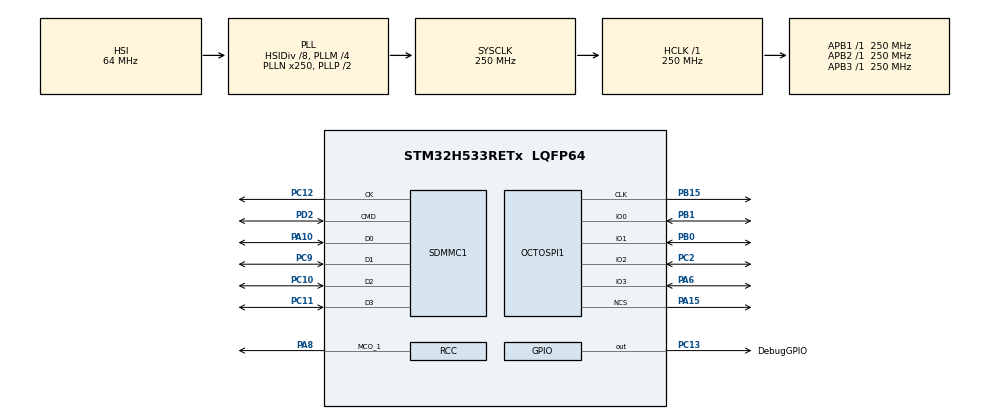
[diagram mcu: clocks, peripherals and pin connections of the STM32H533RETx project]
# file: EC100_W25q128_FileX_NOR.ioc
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BOOTPATH.BootPathName=LEGACY
BOOTPATH.UserSelectedBootPath=LEGACY
CORTEX_M33_NS.userName=CORTEX_M33
FILEX.FILEX_APPLICATION_THREAD_STACK_SIZE=14000
FILEX.FORMAT_NOR_OSPI_MEDIA=0
FILEX.FX_APP_MEM_POOL_SIZE=20000
FILEX.FX_FAT_MAP_SIZE=1024
FILEX.FX_LX_NOR_INTERFACE=1
FILEX.FX_MEDIA_DISABLE_SEARCH_CACHE=1
FILEX.FX_SD_INTERFACE=1
FILEX.LINK_NOR_OSPI_DRIVER=1
FILEX.LINK_SD_DRIVER=1
FILEX.useRTOS=1
GPDMA1.DESTINC_GPDMACH1=DMA_DINC_INCREMENTED
GPDMA1.DIRECTION_GPDMACH0=DMA_MEMORY_TO_PERIPH
GPDMA1.DMAHANDLE_GPDMACH0=hdmatx
GPDMA1.IPHANDLE_GPDMACH0-SIMPLEREQUEST_GPDMACH0=__NULL
GPDMA1.IPHANDLE_GPDMACH1-SIMPLEREQUEST_GPDMACH1=__NULL
GPDMA1.REQUEST_GPDMACH0=GPDMA1_REQUEST_OCTOSPI1
GPDMA1.REQUEST_GPDMACH1=GPDMA1_REQUEST_OCTOSPI1
GPDMA1.SRCINC_GPDMACH0=DMA_SINC_INCREMENTED
LEVELX.LX_DIRECT_READ=0
LEVELX.LX_DRIVER_CALLS_OSPI_INIT=0
LEVELX.LX_DRIVER_ERASES_OSPI_AFTER_INIT=0
LEVELX.LX_FREE_SECTOR_DATA_VERIFY=0
LEVELX.LX_NOR_ENABLE_MAPPING_BITMAP=1
LEVELX.LX_NOR_ENABLE_OBSOLETE_COUNT_CACHE=1
LEVELX.LX_NOR_Flash_Support=1
LEVELX.LX_NOR_SECTOR_SIZE=512
LEVELX.LX_OctoSPI_Memory_Interface=1
LevelX.BSP.number=1
LevelX0.BSP.STBoard=false
LevelX0.BSP.api=BSP_COMPONENT_DRIVER
LevelX0.BSP.component=custom
LevelX0.BSP.instance=custom
LevelX0.BSP.name=OSPI Component
LevelX0.BSP.semaphore=SEMA_CUSTOM
LevelX0.BSP.solution=custom
Mcu.Family=STM32H5
Mcu.Name=STM32H533RETx
Mcu.Package=LQFP64
NVIC.GPDMA1_Channel0_IRQn=true\:0\:0\:false\:false\:true\:false\:true\:true\:true
NVIC.GPDMA1_Channel1_IRQn=true\:0\:0\:false\:false\:true\:false\:true\:true\:true
NVIC.OCTOSPI1_IRQn=true\:0\:0\:false\:false\:true\:false\:true\:true\:true
NVIC.PriorityGroup=NVIC_PRIORITYGROUP_4
NVIC.SDMMC1_IRQn=true\:0\:0\:false\:false\:true\:false\:true\:true\:true
NVIC.TIM6_IRQn=true\:15\:0\:false\:false\:true\:false\:false\:true\:true
NVIC.TimeBase=TIM6_IRQn
NVIC.TimeBaseIP=TIM6
OCTOSPI1.ChipSelectHighTimeCycle=1
OCTOSPI1.ClockMode=HAL_XSPI_CLOCK_MODE_3
OCTOSPI1.ClockPrescaler=2
OCTOSPI1.MemorySize=HAL_XSPI_SIZE_128MB
OCTOSPI1.MemoryType=HAL_XSPI_MEMTYPE_MACRONIX
PA0.Signal=SPI3_RDY
PA10.Mode=SD_4_bits_Wide_bus
PA10.Signal=SDMMC1_D0
PA11.Signal=FDCAN1_RX
PA12.Signal=FDCAN1_TX
PA13(JTMS/SWDIO).Mode=Serial_Wire
PA13(JTMS/SWDIO).Signal=DEBUG_JTMS-SWDIO
PA14(JTCK/SWCLK).Mode=Serial_Wire
PA14(JTCK/SWCLK).Signal=DEBUG_JTCK-SWCLK
PA15(JTDI).Mode=quad_mode
PA15(JTDI).Signal=OCTOSPI1_NCS
PA2.Signal=USART2_TX
PA3.Signal=USART2_RX
PA4.Signal=COMP_DAC11_group
PA5.Signal=COMP_DAC12_group
PA6.Mode=OCTOSPI1_IO[3\:0]
PA6.Signal=OCTOSPI1_IO3
PA7.Signal=ADCx_INP7
PA8.Mode=Clock-out
PA8.Signal=RCC_MCO_1
PA9.Signal=SPI2_SCK
PB0.Mode=OCTOSPI1_IO[3\:0]
PB0.Signal=OCTOSPI1_IO1
PB1.Mode=OCTOSPI1_IO[3\:0]
PB1.Signal=OCTOSPI1_IO0
PB10.Signal=USART3_TX
PB12.Signal=SPI2_NSS
PB13.Signal=UART5_TX
PB14.Signal=SPI2_MISO
PB15.Mode=quad_mode
PB15.Signal=OCTOSPI1_CLK
PB2.Signal=SPI3_MOSI
PB3(JTDO/TRACESWO).Signal=SPI3_SCK
PB4(NJTRST).Signal=SPI3_MISO
PB5.Signal=UART5_RX
PB6.Signal=I2C1_SCL
PB7.Signal=I2C1_SDA
PB8.Signal=SPI3_NSS
PC0.Signal=ADCx_INP10
PC1.Signal=ADCx_INP11
PC10.Mode=SD_4_bits_Wide_bus
PC10.Signal=SDMMC1_D2
PC11.Mode=SD_4_bits_Wide_bus
PC11.Signal=SDMMC1_D3
PC12.Mode=SD_4_bits_Wide_bus
PC12.Signal=SDMMC1_CK
PC13.GPIO_Label=DebugGPIO
PC13.Signal=GPIO_Output
PC14-OSC32_IN(OSC32_IN).Signal=RCC_OSC32_IN
PC15-OSC32_OUT(OSC32_OUT).Signal=RCC_OSC32_OUT
PC2.Mode=OCTOSPI1_IO[3\:0]
PC2.Signal=OCTOSPI1_IO2
PC3.Signal=SPI2_MOSI
PC4.Signal=USART3_RX
PC5.Signal=ADCx_INP8
PC6.Signal=USART6_TX
PC7.Signal=USART6_RX
PC8.Signal=UART5_DE
PC9.Mode=SD_4_bits_Wide_bus
PC9.Signal=SDMMC1_D1
PD2.Mode=SD_4_bits_Wide_bus
PD2.Signal=SDMMC1_CMD
PH0-OSC_IN(PH0).Signal=RCC_OSC_IN
PH1-OSC_OUT(PH1).Signal=RCC_OSC_OUT
ProjectManager.HeapSize=0x200
ProjectManager.StackSize=0x400
ProjectManager.TargetToolchain=STM32CubeIDE
RCC.ADCFreq_Value=250000000
RCC.AHBFreq_Value=250000000
RCC.APB1Freq_Value=250000000
RCC.APB1TimFreq_Value=250000000
RCC.APB2Freq_Value=250000000
RCC.APB2TimFreq_Value=250000000
RCC.APB3Freq_Value=250000000
RCC.CSI_VALUE=4000000
RCC.CortexFreq_Value=250000000
RCC.EPOD_VALUE=8000000
RCC.HCLKFreq_Value=250000000
RCC.HSE_VALUE=25000000
RCC.HSI48_VALUE=48000000
RCC.HSIDiv=RCC_HSI_DIV8
RCC.HSI_VALUE=64000000
RCC.LSE_VALUE=32768
RCC.LSIRC_VALUE=32000
RCC.OCTOSPIMCLockSelection=RCC_OSPICLKSOURCE_CLKP
RCC.PLL2M=4
RCC.PLL2N=100
RCC.PLL2R=4
RCC.PLL2Source=RCC_PLL2_SOURCE_HSI
RCC.PLL3N=50
RCC.PLLM=4
RCC.PLLN=250
RCC.PLLSourceVirtual=RCC_PLL1_SOURCE_HSI
RCC.SPI2CLockSelection=RCC_SPI2CLKSOURCE_CLKP
RCC.SPI3CLockSelection=RCC_SPI3CLKSOURCE_PLL3P
RCC.SYSCLKFreq_VALUE=250000000
RCC.SYSCLKSource=RCC_SYSCLKSOURCE_PLLCLK
RCC.USBFreq_Value=48000000
RCC.VCOOutputFreq_Value=500000000
SDMMC1.ClockDiv=0
SH.ADCx_INP10.0=ADC1_INP10
SH.ADCx_INP11.0=ADC1_INP11
SH.ADCx_INP7.0=ADC1_INP7
SH.ADCx_INP8.0=ADC1_INP8
SH.COMP_DAC11_group.0=DAC1_OUT1
SH.COMP_DAC12_group.0=DAC1_OUT2
STMicroelectronics.X-CUBE-FREERTOS.1.3.1.configUSE_NEWLIB_REENTRANT=1
VP_BOOTPATH_VS_BOOTPATH.Mode=BP_Activate
VP_CORTEX_M33_NS_VS_Hclk.Mode=Hclk_Mode
VP_DCACHE1_VS_DCACHE.Mode=DCACHE_Activate
VP_FILEX_VS_FileOoSystemJjFileXJjCore.Mode=FileX_Core
VP_FILEX_VS_LevelXOoNOROointerface.Mode=LevelX_NOR_interface
VP_FILEX_VS_SDOointerface.Mode=SD_interface
VP_GPDMA1_VS_GPDMACH0.Mode=SIMPLEREQUEST_GPDMACH0
VP_GPDMA1_VS_GPDMACH1.Mode=SIMPLEREQUEST_GPDMACH1
VP_ICACHE_VS_ICACHE.Mode=DefaultMode
VP_LEVELX_VS_FileOoSystemJjLevelXJjNOR.Mode=LevelX_NOR_Flash_Support
VP_LEVELX_VS_OctoSPIOomemoryOointerface.Mode=OctoSPI_memory_interface
VP_MEMORYMAP_VS_MEMORYMAP.Mode=CurAppReg
VP_PWR_VS_LPOM.Mode=PowerOptimisation
VP_PWR_VS_SECSignals.Mode=Security/Privilege
VP_SYS_VS_tim6.Mode=TIM6
VP_THREADX_VS_RTOSJjThreadXJjCoreJjDefault.Mode=Core_Default
board=custom

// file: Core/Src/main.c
/* USER CODE BEGIN Header */
/**
  ******************************************************************************
  * @file           : main.c
  * @brief          : Main program body
  ******************************************************************************
  * @attention
  *
  * Copyright (c) 2025 STMicroelectronics.
  * All rights reserved.
  *
  * This software is licensed under terms that can be found in the LICENSE file
  * in the root directory of this software component.
  * If no LICENSE file comes with this software, it is provided AS-IS.
  *
  ******************************************************************************
  */
/* USER CODE END Header */
#include "app_threadx.h"
#include "main.h"

DCACHE_HandleTypeDef hdcache1;

XSPI_HandleTypeDef hospi1;
DMA_HandleTypeDef handle_GPDMA1_Channel1;
DMA_HandleTypeDef handle_GPDMA1_Channel0;

SD_HandleTypeDef hsd1;

void SystemClock_Config(void);
void PeriphCommonClock_Config(void);
static void MX_GPIO_Init(void);
static void MX_GPDMA1_Init(void);
static void MX_OCTOSPI1_Init(void);
static void MX_ICACHE_Init(void);
static void MX_DCACHE1_Init(void);
static void MX_SDMMC1_SD_Init(void);
/* USER CODE BEGIN PFP */

void W25Q128EnableWrite(void);
void W25Q128BorradoCompleto();
extern void Formateo();
/* USER CODE END PFP */

int main(void)
{

  /* MCU Configuration--------------------------------------------------------*/

  /* Reset of all peripherals, Initializes the Flash interface and the Systick. */
  HAL_Init();

  /* Configure the system clock */
  SystemClock_Config();

  /* Configure the peripherals common clocks */
  PeriphCommonClock_Config();

  /* Initialize all configured peripherals */
  MX_GPIO_Init();
  MX_GPDMA1_Init();
  MX_OCTOSPI1_Init();
  MX_ICACHE_Init();
  MX_DCACHE1_Init();
  MX_SDMMC1_SD_Init();

  MX_ThreadX_Init();

  /* We should never get here as control is now taken by the scheduler */

  /* Infinite loop */
  while (1)
  {

  }
}

void SystemClock_Config(void)
{
  RCC_OscInitTypeDef RCC_OscInitStruct = {0};
  RCC_ClkInitTypeDef RCC_ClkInitStruct = {0};

  /** Configure the main internal regulator output voltage
  */
  __HAL_PWR_VOLTAGESCALING_CONFIG(PWR_REGULATOR_VOLTAGE_SCALE0);

  while(!__HAL_PWR_GET_FLAG(PWR_FLAG_VOSRDY)) {}

  /** Initializes the RCC Oscillators according to the specified parameters
  * in the RCC_OscInitTypeDef structure.
  */
  RCC_OscInitStruct.OscillatorType = RCC_OSCILLATORTYPE_HSI;
  RCC_OscInitStruct.HSIState = RCC_HSI_ON;
  RCC_OscInitStruct.HSIDiv = RCC_HSI_DIV8;
  RCC_OscInitStruct.HSICalibrationValue = RCC_HSICALIBRATION_DEFAULT;
  RCC_OscInitStruct.PLL.PLLState = RCC_PLL_ON;
  RCC_OscInitStruct.PLL.PLLSource = RCC_PLL1_SOURCE_HSI;
  RCC_OscInitStruct.PLL.PLLM = 4;
  RCC_OscInitStruct.PLL.PLLN = 250;
  RCC_OscInitStruct.PLL.PLLP = 2;
  RCC_OscInitStruct.PLL.PLLQ = 2;
  RCC_OscInitStruct.PLL.PLLR = 2;
  RCC_OscInitStruct.PLL.PLLRGE = RCC_PLL1_VCIRANGE_1;
  RCC_OscInitStruct.PLL.PLLVCOSEL = RCC_PLL1_VCORANGE_WIDE;
  RCC_OscInitStruct.PLL.PLLFRACN = 0;
  if (HAL_RCC_OscConfig(&RCC_OscInitStruct) != HAL_OK)
  {
    Error_Handler();
  }

  /** Initializes the CPU, AHB and APB buses clocks
  */
  RCC_ClkInitStruct.ClockType = RCC_CLOCKTYPE_HCLK|RCC_CLOCKTYPE_SYSCLK
                              |RCC_CLOCKTYPE_PCLK1|RCC_CLOCKTYPE_PCLK2
                              |RCC_CLOCKTYPE_PCLK3;
  RCC_ClkInitStruct.SYSCLKSource = RCC_SYSCLKSOURCE_PLLCLK;
  RCC_ClkInitStruct.AHBCLKDivider = RCC_SYSCLK_DIV1;
  RCC_ClkInitStruct.APB1CLKDivider = RCC_HCLK_DIV1;
  RCC_ClkInitStruct.APB2CLKDivider = RCC_HCLK_DIV1;
  RCC_ClkInitStruct.APB3CLKDivider = RCC_HCLK_DIV1;

  if (HAL_RCC_ClockConfig(&RCC_ClkInitStruct, FLASH_LATENCY_5) != HAL_OK)
  {
    Error_Handler();
  }
  HAL_RCC_MCOConfig(RCC_MCO1, RCC_MCO1SOURCE_HSI, RCC_MCODIV_1);

  /** Configure the programming delay
  */
  __HAL_FLASH_SET_PROGRAM_DELAY(FLASH_PROGRAMMING_DELAY_2);
}

void PeriphCommonClock_Config(void)
{
  RCC_PeriphCLKInitTypeDef PeriphClkInitStruct = {0};

  /** Initializes the peripherals clock
  */
  PeriphClkInitStruct.PeriphClockSelection = RCC_PERIPHCLK_CKPER;
  PeriphClkInitStruct.CkperClockSelection = RCC_CLKPSOURCE_HSI;
  if (HAL_RCCEx_PeriphCLKConfig(&PeriphClkInitStruct) != HAL_OK)
  {
    Error_Handler();
  }
}

static void MX_DCACHE1_Init(void)
{

  hdcache1.Instance = DCACHE1;
  hdcache1.Init.ReadBurstType = DCACHE_READ_BURST_WRAP;
  if (HAL_DCACHE_Init(&hdcache1) != HAL_OK)
  {
    Error_Handler();
  }

}

static void MX_GPDMA1_Init(void)
{

  /* Peripheral clock enable */
  __HAL_RCC_GPDMA1_CLK_ENABLE();

  /* GPDMA1 interrupt Init */
    HAL_NVIC_SetPriority(GPDMA1_Channel0_IRQn, 0, 0);
    HAL_NVIC_EnableIRQ(GPDMA1_Channel0_IRQn);
    HAL_NVIC_SetPriority(GPDMA1_Channel1_IRQn, 0, 0);
    HAL_NVIC_EnableIRQ(GPDMA1_Channel1_IRQn);

}

static void MX_ICACHE_Init(void)
{

  /** Enable instruction cache (default 2-ways set associative cache)
  */
  if (HAL_ICACHE_Enable() != HAL_OK)
  {
    Error_Handler();
  }

}

static void MX_OCTOSPI1_Init(void)
{

  /* OCTOSPI1 parameter configuration*/
  hospi1.Instance = OCTOSPI1;
  hospi1.Init.FifoThresholdByte = 1;
  hospi1.Init.MemoryMode = HAL_XSPI_SINGLE_MEM;
  hospi1.Init.MemoryType = HAL_XSPI_MEMTYPE_MACRONIX;
  hospi1.Init.MemorySize = HAL_XSPI_SIZE_128MB;
  hospi1.Init.ChipSelectHighTimeCycle = 1;
  hospi1.Init.FreeRunningClock = HAL_XSPI_FREERUNCLK_DISABLE;
  hospi1.Init.ClockMode = HAL_XSPI_CLOCK_MODE_3;
  hospi1.Init.WrapSize = HAL_XSPI_WRAP_NOT_SUPPORTED;
  hospi1.Init.ClockPrescaler = 2;
  hospi1.Init.SampleShifting = HAL_XSPI_SAMPLE_SHIFT_NONE;
  hospi1.Init.DelayHoldQuarterCycle = HAL_XSPI_DHQC_DISABLE;
  hospi1.Init.ChipSelectBoundary = HAL_XSPI_BONDARYOF_NONE;
  hospi1.Init.DelayBlockBypass = HAL_XSPI_DELAY_BLOCK_BYPASS;
  hospi1.Init.Refresh = 0;
  if (HAL_XSPI_Init(&hospi1) != HAL_OK)
  {
    Error_Handler();
  }

}

static void MX_SDMMC1_SD_Init(void)
{

  hsd1.Instance = SDMMC1;
  hsd1.Init.ClockEdge = SDMMC_CLOCK_EDGE_RISING;
  hsd1.Init.ClockPowerSave = SDMMC_CLOCK_POWER_SAVE_DISABLE;
  hsd1.Init.BusWide = SDMMC_BUS_WIDE_4B;
  hsd1.Init.HardwareFlowControl = SDMMC_HARDWARE_FLOW_CONTROL_DISABLE;
  hsd1.Init.ClockDiv = 0;
  if (HAL_SD_Init(&hsd1) != HAL_OK)
  {
    Error_Handler();
  }

}

static void MX_GPIO_Init(void)
{
  GPIO_InitTypeDef GPIO_InitStruct = {0};

  /* GPIO Ports Clock Enable */
  __HAL_RCC_GPIOC_CLK_ENABLE();
  __HAL_RCC_GPIOH_CLK_ENABLE();
  __HAL_RCC_GPIOA_CLK_ENABLE();
  __HAL_RCC_GPIOB_CLK_ENABLE();
  __HAL_RCC_GPIOD_CLK_ENABLE();

  /*Configure GPIO pin Output Level */
  HAL_GPIO_WritePin(DebugGPIO_GPIO_Port, DebugGPIO_Pin, GPIO_PIN_RESET);

  /*Configure GPIO pin : DebugGPIO_Pin */
  GPIO_InitStruct.Pin = DebugGPIO_Pin;
  GPIO_InitStruct.Mode = GPIO_MODE_OUTPUT_PP;
  GPIO_InitStruct.Pull = GPIO_NOPULL;
  GPIO_InitStruct.Speed = GPIO_SPEED_FREQ_LOW;
  HAL_GPIO_Init(DebugGPIO_GPIO_Port, &GPIO_InitStruct);

  /*Configure GPIO pins : PC0 PC1 PC5 */
  GPIO_InitStruct.Pin = GPIO_PIN_0|GPIO_PIN_1|GPIO_PIN_5;
  GPIO_InitStruct.Mode = GPIO_MODE_ANALOG;
  GPIO_InitStruct.Pull = GPIO_NOPULL;
  HAL_GPIO_Init(GPIOC, &GPIO_InitStruct);

  /*Configure GPIO pin : PC3 */
  GPIO_InitStruct.Pin = GPIO_PIN_3;
  GPIO_InitStruct.Mode = GPIO_MODE_AF_PP;
  GPIO_InitStruct.Pull = GPIO_NOPULL;
  GPIO_InitStruct.Speed = GPIO_SPEED_FREQ_LOW;
  GPIO_InitStruct.Alternate = GPIO_AF5_SPI2;
  HAL_GPIO_Init(GPIOC, &GPIO_InitStruct);

  /*Configure GPIO pin : PA0 */
  GPIO_InitStruct.Pin = GPIO_PIN_0;
  GPIO_InitStruct.Mode = GPIO_MODE_AF_PP;
  GPIO_InitStruct.Pull = GPIO_NOPULL;
  GPIO_InitStruct.Speed = GPIO_SPEED_FREQ_LOW;
  GPIO_InitStruct.Alternate = GPIO_AF6_SPI3;
  HAL_GPIO_Init(GPIOA, &GPIO_InitStruct);

  /*Configure GPIO pins : PA2 PA3 */
  GPIO_InitStruct.Pin = GPIO_PIN_2|GPIO_PIN_3;
  GPIO_InitStruct.Mode = GPIO_MODE_AF_PP;
  GPIO_InitStruct.Pull = GPIO_NOPULL;
  GPIO_InitStruct.Speed = GPIO_SPEED_FREQ_LOW;
  GPIO_InitStruct.Alternate = GPIO_AF7_USART2;
  HAL_GPIO_Init(GPIOA, &GPIO_InitStruct);

  /*Configure GPIO pins : PA4 PA5 PA7 */
  GPIO_InitStruct.Pin = GPIO_PIN_4|GPIO_PIN_5|GPIO_PIN_7;
  GPIO_InitStruct.Mode = GPIO_MODE_ANALOG;
  GPIO_InitStruct.Pull = GPIO_NOPULL;
  HAL_GPIO_Init(GPIOA, &GPIO_InitStruct);

  /*Configure GPIO pin : PC4 */
  GPIO_InitStruct.Pin = GPIO_PIN_4;
  GPIO_InitStruct.Mode = GPIO_MODE_AF_PP;
  GPIO_InitStruct.Pull = GPIO_NOPULL;
  GPIO_InitStruct.Speed = GPIO_SPEED_FREQ_LOW;
  GPIO_InitStruct.Alternate = GPIO_AF7_USART3;
  HAL_GPIO_Init(GPIOC, &GPIO_InitStruct);

  /*Configure GPIO pin : PB2 */
  GPIO_InitStruct.Pin = GPIO_PIN_2;
  GPIO_InitStruct.Mode = GPIO_MODE_AF_PP;
  GPIO_InitStruct.Pull = GPIO_NOPULL;
  GPIO_InitStruct.Speed = GPIO_SPEED_FREQ_LOW;
  GPIO_InitStruct.Alternate = GPIO_AF7_SPI3;
  HAL_GPIO_Init(GPIOB, &GPIO_InitStruct);

  /*Configure GPIO pin : PB10 */
  GPIO_InitStruct.Pin = GPIO_PIN_10;
  GPIO_InitStruct.Mode = GPIO_MODE_AF_PP;
  GPIO_InitStruct.Pull = GPIO_NOPULL;
  GPIO_InitStruct.Speed = GPIO_SPEED_FREQ_LOW;
  GPIO_InitStruct.Alternate = GPIO_AF7_USART3;
  HAL_GPIO_Init(GPIOB, &GPIO_InitStruct);

  /*Configure GPIO pins : PB12 PB14 */
  GPIO_InitStruct.Pin = GPIO_PIN_12|GPIO_PIN_14;
  GPIO_InitStruct.Mode = GPIO_MODE_AF_PP;
  GPIO_InitStruct.Pull = GPIO_NOPULL;
  GPIO_InitStruct.Speed = GPIO_SPEED_FREQ_LOW;
  GPIO_InitStruct.Alternate = GPIO_AF5_SPI2;
  HAL_GPIO_Init(GPIOB, &GPIO_InitStruct);

  /*Configure GPIO pins : PB13 PB5 */
  GPIO_InitStruct.Pin = GPIO_PIN_13|GPIO_PIN_5;
  GPIO_InitStruct.Mode = GPIO_MODE_AF_PP;
  GPIO_InitStruct.Pull = GPIO_NOPULL;
  GPIO_InitStruct.Speed = GPIO_SPEED_FREQ_LOW;
  GPIO_InitStruct.Alternate = GPIO_AF14_UART5;
  HAL_GPIO_Init(GPIOB, &GPIO_InitStruct);

  /*Configure GPIO pins : PC6 PC7 */
  GPIO_InitStruct.Pin = GPIO_PIN_6|GPIO_PIN_7;
  GPIO_InitStruct.Mode = GPIO_MODE_AF_PP;
  GPIO_InitStruct.Pull = GPIO_NOPULL;
  GPIO_InitStruct.Speed = GPIO_SPEED_FREQ_LOW;
  GPIO_InitStruct.Alternate = GPIO_AF7_USART6;
  HAL_GPIO_Init(GPIOC, &GPIO_InitStruct);

  /*Configure GPIO pin : PC8 */
  GPIO_InitStruct.Pin = GPIO_PIN_8;
  GPIO_InitStruct.Mode = GPIO_MODE_AF_PP;
  GPIO_InitStruct.Pull = GPIO_NOPULL;
  GPIO_InitStruct.Speed = GPIO_SPEED_FREQ_LOW;
  GPIO_InitStruct.Alternate = GPIO_AF8_UART5;
  HAL_GPIO_Init(GPIOC, &GPIO_InitStruct);

  /*Configure GPIO pin : PA8 */
  GPIO_InitStruct.Pin = GPIO_PIN_8;
  GPIO_InitStruct.Mode = GPIO_MODE_AF_PP;
  GPIO_InitStruct.Pull = GPIO_NOPULL;
  GPIO_InitStruct.Speed = GPIO_SPEED_FREQ_LOW;
  GPIO_InitStruct.Alternate = GPIO_AF0_MCO;
  HAL_GPIO_Init(GPIOA, &GPIO_InitStruct);

  /*Configure GPIO pin : PA9 */
  GPIO_InitStruct.Pin = GPIO_PIN_9;
  GPIO_InitStruct.Mode = GPIO_MODE_AF_PP;
  GPIO_InitStruct.Pull = GPIO_NOPULL;
  GPIO_InitStruct.Speed = GPIO_SPEED_FREQ_LOW;
  GPIO_InitStruct.Alternate = GPIO_AF5_SPI2;
  HAL_GPIO_Init(GPIOA, &GPIO_InitStruct);

  /*Configure GPIO pins : PA11 PA12 */
  GPIO_InitStruct.Pin = GPIO_PIN_11|GPIO_PIN_12;
  GPIO_InitStruct.Mode = GPIO_MODE_AF_PP;
  GPIO_InitStruct.Pull = GPIO_NOPULL;
  GPIO_InitStruct.Speed = GPIO_SPEED_FREQ_LOW;
  GPIO_InitStruct.Alternate = GPIO_AF9_FDCAN1;
  HAL_GPIO_Init(GPIOA, &GPIO_InitStruct);

  /*Configure GPIO pins : PB3 PB4 PB8 */
  GPIO_InitStruct.Pin = GPIO_PIN_3|GPIO_PIN_4|GPIO_PIN_8;
  GPIO_InitStruct.Mode = GPIO_MODE_AF_PP;
  GPIO_InitStruct.Pull = GPIO_NOPULL;
  GPIO_InitStruct.Speed = GPIO_SPEED_FREQ_LOW;
  GPIO_InitStruct.Alternate = GPIO_AF6_SPI3;
  HAL_GPIO_Init(GPIOB, &GPIO_InitStruct);

  /*Configure GPIO pins : PB6 PB7 */
  GPIO_InitStruct.Pin = GPIO_PIN_6|GPIO_PIN_7;
  GPIO_InitStruct.Mode = GPIO_MODE_AF_OD;
  GPIO_InitStruct.Pull = GPIO_NOPULL;
  GPIO_InitStruct.Speed = GPIO_SPEED_FREQ_LOW;
  GPIO_InitStruct.Alternate = GPIO_AF4_I2C1;
  HAL_GPIO_Init(GPIOB, &GPIO_InitStruct);

}

/* USER CODE BEGIN 4 */
void W25Q128BorradoCompleto()
{
	W25Q128EnableWrite();
	XSPI_RegularCmdTypeDef CMD ={ 0 };
	CMD.Instruction = 0xc7;
	CMD.InstructionMode = HAL_XSPI_INSTRUCTION_1_LINE;
	HAL_XSPI_Command(&hospi1, &CMD, 1);
}
void W25Q128EnableWrite(void)
{
	XSPI_RegularCmdTypeDef CMD = {0};
	CMD.Instruction = 0x06;
	CMD.InstructionMode = HAL_XSPI_INSTRUCTION_1_LINE;
	HAL_XSPI_Command (&hospi1, &CMD, 1);
}
/* USER CODE END 4 */

void HAL_TIM_PeriodElapsedCallback(TIM_HandleTypeDef *htim)
{
  if (htim->Instance == TIM6)
  {
    HAL_IncTick();
  }
}

void Error_Handler(void)
{
  __disable_irq();
  while (1)
  {
  }
}
